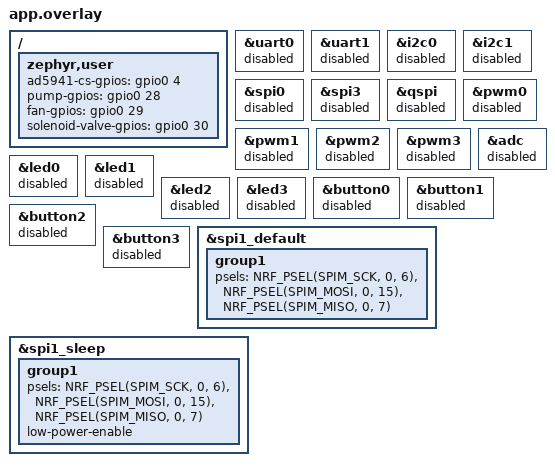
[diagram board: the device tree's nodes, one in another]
&uart0 { status = "disabled"; };
&uart1 { status = "disabled"; };
&i2c0 { status = "disabled"; };
&i2c1 { status = "disabled"; };
&spi0 { status = "disabled"; };
// &spi1 { status = "disabled"; };
&spi3 { status = "disabled"; };
&qspi { status = "disabled"; };
&pwm0 { status = "disabled"; };
&pwm1 { status = "disabled"; };
&pwm2 { status = "disabled"; };
&pwm3 { status = "disabled"; };
&adc { status = "disabled"; };
// &gpio0 { status = "disabled"; };
// &gpio1 { status = "disabled"; };
// &flash_controller { status = "disabled"; };
// &cryptocell { status = "disabled"; };
// &rtc0 { status = "disabled"; };
// &rtc1 { status = "disabled"; };
// &timer0 { status = "disabled"; };
// &timer1 { status = "disabled"; };
// &timer2 { status = "disabled"; };
// &timer3 { status = "disabled"; };
// &timer4 { status = "disabled"; };

// /* Disable the LEDs and buttons */
&led0 { status = "disabled"; };
&led1 { status = "disabled"; };
&led2 { status = "disabled"; };
&led3 { status = "disabled"; };
&button0 { status = "disabled"; };
&button1 { status = "disabled"; };
&button2 { status = "disabled"; };
&button3 { status = "disabled"; };

/ {
	zephyr,user {
		ad5941-cs-gpios = <&gpio0 4 0>;
		pump-gpios = <&gpio0 28 0>;
		fan-gpios = <&gpio0 29 0>;
		solenoid-valve-gpios = <&gpio0 30 0>;
	};
};

&spi1_default {
	group1 {
		psels = <NRF_PSEL(SPIM_SCK, 0, 6)>,
				<NRF_PSEL(SPIM_MOSI, 0, 15)>,
				<NRF_PSEL(SPIM_MISO, 0, 7)>;
	};
};

&spi1_sleep {
	group1 {
		psels = <NRF_PSEL(SPIM_SCK, 0, 6)>,
				<NRF_PSEL(SPIM_MOSI, 0, 15)>,
				<NRF_PSEL(SPIM_MISO, 0, 7)>;
		low-power-enable;
	};
};
